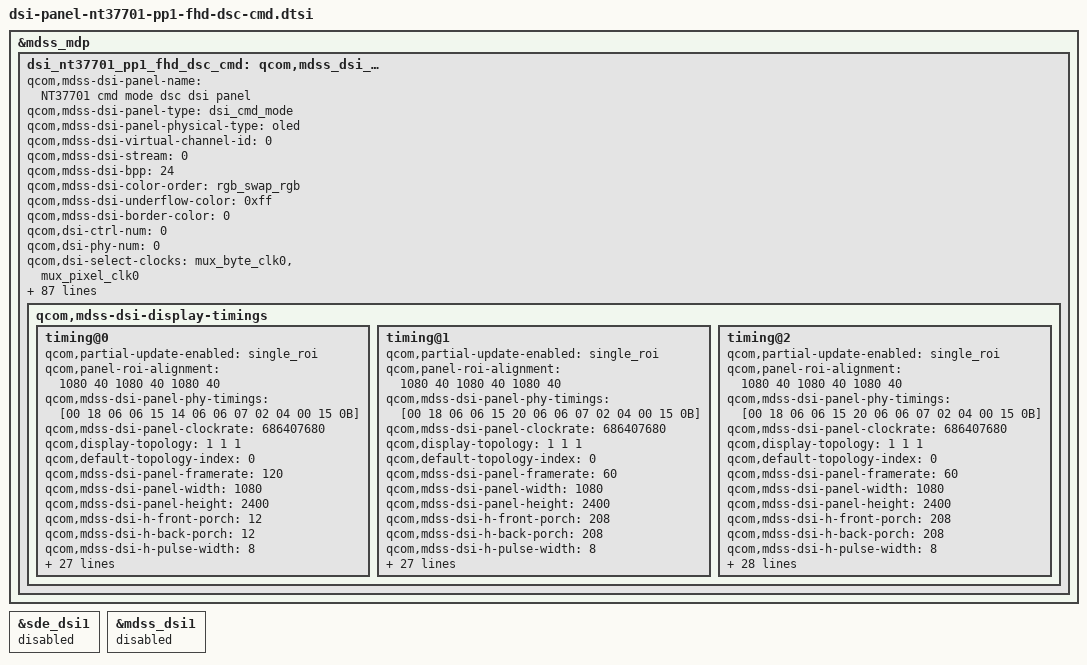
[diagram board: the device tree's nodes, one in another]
/* Copyright (c) 2014, Code Aurora Forum. All rights reserved.
 *
 * This program is free software; you can redistribute it and/or modify
 * it under the terms of the GNU General Public License version 2 and
 * only version 2 as published by the Free Software Foundation.
 *
 * This program is distributed in the hope that it will be useful,
 * but WITHOUT ANY WARRANTY; without even the implied warranty of
 * MERCHANTABILITY or FITNESS FOR A PARTICULAR PURPOSE.  See the
 * GNU General Public License for more details.
 */

&mdss_mdp {
    dsi_nt37701_pp1_fhd_dsc_cmd: qcom,mdss_dsi_nt37701_pp1_fhd_dsc_cmd {
        qcom,mdss-dsi-panel-name = "NT37701 cmd mode dsc dsi panel";
		qcom,mdss-dsi-panel-type = "dsi_cmd_mode";
		qcom,mdss-dsi-panel-physical-type = "oled";
		qcom,mdss-dsi-virtual-channel-id = <0>;
		qcom,mdss-dsi-stream = <0>;
		qcom,mdss-dsi-bpp = <24>;
		qcom,mdss-dsi-color-order = "rgb_swap_rgb";
		qcom,mdss-dsi-underflow-color = <0xff>;
		qcom,mdss-dsi-border-color = <0>;
		qcom,dsi-ctrl-num = <0>;
		qcom,dsi-phy-num = <0>;
		qcom,dsi-select-clocks = "mux_byte_clk0", "mux_pixel_clk0";
		qcom,mdss-dsi-traffic-mode = "burst_mode";
		qcom,mdss-dsi-lane-map = "lane_map_0123";
		qcom,mdss-dsi-bllp-eof-power-mode;
		qcom,mdss-dsi-bllp-power-mode;
		qcom,mdss-dsi-lane-0-state;
		qcom,mdss-dsi-lane-1-state;
		qcom,mdss-dsi-lane-2-state;
		qcom,mdss-dsi-lane-3-state;
		qcom,mdss-dsi-reset-sequence = <1 10>, <0 2>, <1 10>;
		lge,mdss-dsi-reset-keep-high-after-off-cmd = <180>;
		qcom,mdss-dsi-dma-trigger = "trigger_sw";
		qcom,mdss-dsi-mdp-trigger = "none";
		qcom,mdss-dsi-te-pin-select = <1>;
		qcom,mdss-dsi-wr-mem-start = <0x2c>;
		qcom,mdss-dsi-wr-mem-continue = <0x3c>;
		qcom,mdss-dsi-te-dcs-command = <1>;
		//qcom,mdss-dsi-te-check-enable;
		//qcom,mdss-dsi-te-using-te-pin;
		qcom,mdss-dsi-lp11-init;
		qcom,mdss-dsi-tx-eot-append;
		qcom,ulps-enabled;
		//qcom,suspend-ulps-enabled;
		qcom,mdss-pan-physical-width-dimension = <71>;
		qcom,mdss-pan-physical-height-dimension = <157>;


		/********** HDR **********/
		qcom,mdss-dsi-panel-hdr-enabled;
		qcom,mdss-dsi-panel-hdr-color-primaries = <14880 15935 32435 16555 14945 30910 7790 3415>;
		qcom,mdss-dsi-panel-peak-brightness = <5000000>;		/* max. 500nits */
		qcom,mdss-dsi-panel-blackness-level = <6134>;

		/********** Brightness list **********/
		lge,blmap = <
			0
			44 44 44 44 44 44 44 44 44 44 52 60 69 77 85 93 102 110 118 126
			135 143 151 159 167 176 184 192 200 209 217 225 233 242 250 258 271 284 298 311
			324 337 351 364 377 390 404 417 430 443 457 470 483 496 510 523 536 549 563 576
			589 605 622 638 654 670 687 703 719 735 752 768 784 800 817 833 849 865 882 898
			914 931 948 965 979 996 1013 1030 1047 1064 1080 1097 1114 1131 1148 1165 1182 1199 1216 1233
			1250 1267 1283 1300 1317 1334 1351 1368 1382 1396 1411 1425 1439 1453 1468 1482 1496 1510 1525 1539
			1553 1567 1581 1596 1610 1624 1638 1653 1667 1681 1695 1710 1724 1738 1754 1769 1785 1800 1816 1832
			1847 1861 1877 1893 1908 1924 1939 1955 1971 1986 2002 2017 2033 2049 2064 2080 2095 2111 2128 2143
			2158 2173 2188 2203 2218 2233 2248 2263 2278 2293 2309 2324 2339 2354 2369 2384 2399 2414 2429 2444
			2459 2474 2489 2503 2518 2532 2547 2561 2576 2590 2605 2619 2634 2648 2663 2677 2691 2706 2720 2735
			2749 2764 2778 2793 2807 2822 2836 2850 2863 2877 2891 2904 2918 2932 2945 2959 2973 2986 3000 3014
			3028 3041 3055 3069 3082 3096 3110 3123 3137 3151 3164 3178 3193 3207 3222 3237 3252 3266 3281 3296
			3311 3325 3340 3355 3370 3384 3399 3414 3429 3443 3458 3473 3488 3502 3517 3521 3525 3529 3534 3538
			3542 3546 3550 3554 3559 3563 3567 3571 3575 3579 3583 3588 3592 3596 3600 3605 3611 3616 3622 3627
			3633 3638 3644 3649 3655 3660 3666 3671 3677 3682 3687 3693 3698 3704 3709 3715 3720 3726 3731 3737
			3742 3748 3753 3759 3764 3769 3775 3780 3786 3791 3797 3802 3808 3813 3819 3824 3830 3835 3841 3846
			3851 3857 3862 3868 3873 3879 3884 3890 3895 3901 3906 3912 3917 3923 3928 3933 3939 3944 3950 3955
			3961 3966 3972 3977 3983 3988 3994 3999 4005 4010 4016 4021 4027 4033 4038 4044 4050 4055 4061 4067
			4072 4078 4084 4089 4095
		>;

		lge,blmap-daylight = <
			0
			44 44 44 44 44 44 44 44 44 44 54 63 73 83 92 102 112 122 131 141
			151 160 170 180 189 199 209 218 228 238 248 257 267 277 286 296 312 327 343 358
			374 389 405 420 436 451 467 482 498 513 529 544 560 575 591 606 622 637 653 668
			684 702 721 739 758 776 795 813 832 850 869 887 906 924 942 961 979 998 1016 1035
			1053 1071 1090 1108 1127 1145 1164 1182 1200 1219 1237 1255 1273 1292 1310 1328 1347 1365 1383 1402
			1420 1438 1456 1475 1493 1511 1530 1548 1565 1583 1600 1617 1635 1652 1669 1687 1704 1721 1739 1756
			1774 1791 1808 1826 1843 1860 1878 1895 1912 1930 1947 1964 1982 1999 2015 2032 2048 2064 2080 2097
			2113 2130 2147 2163 2179 2195 2212 2228 2244 2261 2277 2293 2309 2326 2342 2358 2375 2391 2406 2422
			2438 2455 2471 2487 2503 2519 2535 2552 2568 2584 2600 2616 2632 2649 2665 2681 2697 2713 2729 2746
			2762 2778 2794 2811 2827 2844 2860 2877 2893 2910 2926 2943 2959 2976 2992 3009 3025 3042 3058 3075
			3091 3108 3124 3141 3157 3174 3190 3206 3223 3239 3255 3272 3288 3304 3321 3337 3353 3370 3386 3402
			3418 3435 3451 3467 3484 3500 3516 3533 3549 3565 3582 3598 3620 3641 3663 3684 3706 3728 3749 3771
			3792 3814 3836 3857 3879 3901 3922 3944 3965 3987 4009 4030 4052 4073 4095 4095 4095 4095 4095 4095
			4095 4095 4095 4095 4095 4095 4095 4095 4095 4095 4095 4095 4095 4095 4095 4095 4095 4095 4095 4095
			4095 4095 4095 4095 4095 4095 4095 4095 4095 4095 4095 4095 4095 4095 4095 4095 4095 4095 4095 4095
			4095 4095 4095 4095 4095 4095 4095 4095 4095 4095 4095 4095 4095 4095 4095 4095 4095 4095 4095 4095
			4095 4095 4095 4095 4095 4095 4095 4095 4095 4095 4095 4095 4095 4095 4095 4095 4095 4095 4095 4095
			4095 4095 4095 4095 4095 4095 4095 4095 4095 4095 4095 4095 4095 4095 4095 4095 4095 4095 4095 4095
			4095 4095 4095 4095 4095
		>;

		lge,blmap-hdr = <
			0
			44 44 44 44 44 44 44 44 44 44 52 60 69 77 85 93 102 110 118 126
			135 143 151 159 167 176 184 192 200 209 217 225 233 242 250 258 271 284 298 311
			324 337 351 364 377 390 404 417 430 443 457 470 483 496 510 523 536 549 563 576
			589 605 622 638 654 670 687 703 719 735 752 768 784 800 817 833 849 865 882 898
			914 931 948 965 979 996 1013 1030 1047 1064 1080 1097 1114 1131 1148 1165 1182 1199 1216 1233
			1250 1267 1283 1300 1317 1334 1351 1368 1382 1396 1411 1425 1439 1453 1468 1482 1496 1510 1525 1539
			1553 1567 1581 1596 1610 1624 1638 1653 1667 1681 1695 1710 1724 1738 1754 1769 1785 1800 1816 1832
			1847 1861 1877 1893 1908 1924 1939 1955 1971 1986 2002 2017 2033 2049 2064 2080 2095 2111 2128 2143
			2158 2173 2188 2203 2218 2233 2248 2263 2278 2293 2309 2324 2339 2354 2369 2384 2399 2414 2429 2444
			2459 2474 2489 2503 2518 2532 2547 2561 2576 2590 2605 2619 2634 2648 2663 2677 2691 2706 2720 2735
			2749 2764 2778 2793 2807 2822 2836 2850 2863 2877 2891 2904 2918 2932 2945 2959 2973 2986 3000 3014
			3028 3041 3055 3069 3082 3096 3110 3123 3137 3151 3164 3178 3193 3207 3222 3237 3252 3266 3281 3296
			3311 3325 3340 3355 3370 3384 3399 3414 3429 3443 3458 3473 3488 3502 3517 3521 3525 3529 3534 3538
			3542 3546 3550 3554 3559 3563 3567 3571 3575 3579 3583 3588 3592 3596 3600 3605 3611 3616 3622 3627
			3633 3638 3644 3649 3655 3660 3666 3671 3677 3682 3687 3693 3698 3704 3709 3715 3720 3726 3731 3737
			3742 3748 3753 3759 3764 3769 3775 3780 3786 3791 3797 3802 3808 3813 3819 3824 3830 3835 3841 3846
			3851 3857 3862 3868 3873 3879 3884 3890 3895 3901 3906 3912 3917 3923 3928 3933 3939 3944 3950 3955
			3961 3966 3972 3977 3983 3988 3994 3999 4005 4010 4016 4021 4027 4033 4038 4044 4050 4055 4061 4067
			4072 4078 4084 4089 4095
		>;

		lge,blmap-hdr-daylight = <
			0
			44 44 44 44 44 44 44 44 44 44 54 63 73 83 92 102 112 122 131 141
			151 160 170 180 189 199 209 218 228 238 248 257 267 277 286 296 312 327 343 358
			374 389 405 420 436 451 467 482 498 513 529 544 560 575 591 606 622 637 653 668
			684 702 721 739 758 776 795 813 832 850 869 887 906 924 942 961 979 998 1016 1035
			1053 1071 1090 1108 1127 1145 1164 1182 1200 1219 1237 1255 1273 1292 1310 1328 1347 1365 1383 1402
			1420 1438 1456 1475 1493 1511 1530 1548 1565 1583 1600 1617 1635 1652 1669 1687 1704 1721 1739 1756
			1774 1791 1808 1826 1843 1860 1878 1895 1912 1930 1947 1964 1982 1999 2015 2032 2048 2064 2080 2097
			2113 2130 2147 2163 2179 2195 2212 2228 2244 2261 2277 2293 2309 2326 2342 2358 2375 2391 2406 2422
			2438 2455 2471 2487 2503 2519 2535 2552 2568 2584 2600 2616 2632 2649 2665 2681 2697 2713 2729 2746
			2762 2778 2794 2811 2827 2844 2860 2877 2893 2910 2926 2943 2959 2976 2992 3009 3025 3042 3058 3075
			3091 3108 3124 3141 3157 3174 3190 3206 3223 3239 3255 3272 3288 3304 3321 3337 3353 3370 3386 3402
			3418 3435 3451 3467 3484 3500 3516 3533 3549 3565 3582 3598 3620 3641 3663 3684 3706 3728 3749 3771
			3792 3814 3836 3857 3879 3901 3922 3944 3965 3987 4009 4030 4052 4073 4095 4095 4095 4095 4095 4095
			4095 4095 4095 4095 4095 4095 4095 4095 4095 4095 4095 4095 4095 4095 4095 4095 4095 4095 4095 4095
			4095 4095 4095 4095 4095 4095 4095 4095 4095 4095 4095 4095 4095 4095 4095 4095 4095 4095 4095 4095
			4095 4095 4095 4095 4095 4095 4095 4095 4095 4095 4095 4095 4095 4095 4095 4095 4095 4095 4095 4095
			4095 4095 4095 4095 4095 4095 4095 4095 4095 4095 4095 4095 4095 4095 4095 4095 4095 4095 4095 4095
			4095 4095 4095 4095 4095 4095 4095 4095 4095 4095 4095 4095 4095 4095 4095 4095 4095 4095 4095 4095
			4095 4095 4095 4095 4095
		>;

		lge,blmap-ex = <
			0
			340 340 340 340 340 340 340 340 340 362 384 406 428 450 472 494 516 538 560 582
			604 626 648 670 692 714 736 758 780 802 824 846 868 890 912 934 954 974 994 1014
			1034 1054 1073 1093 1113 1133 1153 1173 1193 1213 1233 1253 1273 1293 1313 1332 1352 1372 1392 1412
			1432 1452 1472 1492 1512 1532 1552 1572 1591 1611 1631 1651 1671 1691 1711 1746 1780 1815 1850 1885
			1919 1954 1989 2024 2058 2093 2128 2162 2197 2232 2267 2301 2336 2371 2406 2440 2475 2506 2536 2567
			2597 2628 2659 2689 2720 2751 2781 2812 2842 2873 2904 2934 2965 2995 3026 3049 3073 3096 3120 3143
			3167 3190 3214 3237 3261 3284 3308 3331 3355 3378 3402 3425 3449 3472 3524 3576 3628 3679 3731 3783
			3799 3816 3832 3849 3865 3882 3898 3914 3931 3947 3964 3980 3996 4013 4029 4046 4062 4079 4095 4095
			4095 4095 4095 4095 4095 4095 4095 4095 4095 4095 4095 4095 4095 4095 4095 4095 4095 4095 4095 4095
			4095 4095 4095 4095 4095 4095 4095 4095 4095 4095 4095 4095 4095 4095 4095 4095 4095 4095 4095 4095
			4095 4095 4095 4095 4095 4095 4095 4095 4095 4095 4095 4095 4095 4095 4095 4095 4095 4095 4095 4095
			4095 4095 4095 4095 4095 4095 4095 4095 4095 4095 4095 4095 4095 4095 4095 4095 4095 4095 4095 4095
			4095 4095 4095 4095 4095 4095 4095 4095 4095 4095 4095 4095 4095 4095 4095 4095 4095 4095 4095 4095
			4095 4095 4095 4095 4095 4095 4095 4095 4095 4095 4095 4095 4095 4095 4095
		>;
		lge,use-vr-lp-mode;
		lge,mdss-dsi-vr-lp-mode-on-command = [
			39 00 00 00 00 00 06 F0 55 AA 52 08 00
			39 00 00 00 00 00 10 B2 11 00 20 20 00 08 08 00 00 40 30 00 00 00 00
			15 00 00 00 00 00 02 6F 0F
			39 00 00 00 00 00 0C B2 30 20 24 24 24 24 2F FF 00 00 00
			39 01 00 00 00 00 06 F0 55 AA 52 00 00
		];
		lge,mdss-dsi-vr-lp-mode-off-command = [
			39 00 00 00 00 00 06 F0 55 AA 52 08 00
			39 00 00 00 00 00 10 B2 01 00 20 20 00 08 08 00 00 40 30 00 00 00 00
			15 00 00 00 00 00 02 6F 0F
			39 00 00 00 00 00 0C B2 30 20 25 89 25 89 2F FF 00 00 00
			39 01 00 00 00 00 06 F0 55 AA 52 00 00
		];
		lge,mdss-dsi-vr-lp-command-state = "dsi_lp_mode";
		lge,blmap-vr = < 0 1060 >;

		/********** Color Manager **********/
		lge,use-color-manager;
		lge,color-manager-default-status = <1>;
		lge,mdss-dsi-color-manager-mode-table = <0 1>, <1 1>, <2 1>, <3 1>;

		lge,mdss-dsi-disp-ctrl-command-1 = [
			//------------------ CM on/off ---------------------
			15 01 00 00 00 00 02 55 00
		];
		lge,mdss-dsi-disp-ctrl-command-1-state = "dsi_lp_mode";

		lge,mdss-dsi-saturation-command = [
			39 00 00 00 00 00 06 F0 55 AA 52 08 00
			39 00 00 00 00 00 2E D1 35 35 35 35 32 30 30 30 32 2D 2D 29 29 32 32 35 35 35 35 33 32 33 35 35 03 01 01 01 01 01 01 01 02 01 01 01 01 06 0C 03 09 0F 68 88 00
			39 01 00 00 00 00 06 F0 55 AA 52 00 00
		];
		lge,mdss-dsi-saturation-command-state = "dsi_hs_mode";

		lge,mdss-dsi-hue-command = [
			39 00 00 00 00 00 06 F0 55 AA 52 08 00
			39 00 00 00 00 00 34 D2 77 0C 40 80 80 8E 80 80 80 80 40 40 40 80 80 80 AD AD A0 80 80 80 80 80 80 80 80 80 80 80 80 80 80 80 80 80 80 80 80 80 80 80 80 80 80 80 80 80 80 80 80
			39 01 00 00 00 00 06 F0 55 AA 52 00 00
		];
		lge,mdss-dsi-hue-command-state = "dsi_hs_mode";

		lge,mdss-dsi-sharpness-command = [
			39 00 00 00 00 00 06 F0 55 AA 52 08 00
			39 00 00 00 00 00 07 D3 02 00 00 01 10 00
			39 01 00 00 00 00 06 F0 55 AA 52 00 00
		];
		lge,mdss-dsi-sharpness-command-state = "dsi_hs_mode";

		lge,mdss-dsi-cm-natural = [
			39 00 00 00 00 00 06 F0 55 AA 52 08 00
			15 00 00 00 00 00 02 6F 00
			39 00 00 00 00 00 13 CE 00 40 40 40 40 3D 3D 3D 3D 40 40 40 40 40 40 40 40 40
			15 00 00 00 00 00 02 6F 13
			39 00 00 00 00 00 12 CE 45 45 45 45 45 45 45 45 45 45 45 45 45 45 45 45 40
			15 00 00 00 00 00 02 6F 24
			39 00 00 00 00 00 12 CE 42 42 42 42 42 42 42 42 42 42 42 42 42 42 42 40 40
			15 00 00 00 00 00 02 6F 35
			39 00 00 00 00 00 12 CE 40 40 40 40 40 40 40 40 40 40 40 40 40 40 40 40 40
			39 00 00 00 00 00 2E D1 32 33 32 35 32 30 30 2F 2D 2D 2D 29 29 29 32 35 35 35 35 33 32 33 35 35 03 01 01 01 01 01 01 01 02 01 01 01 01 06 0C 03 09 0F 68 88 00
			39 00 00 00 00 00 34 D2 77 0C 40 80 80 7F 80 80 80 80 80 80 80 80 80 80 A8 A8 A0 80 80 80 80 80 80 80 80 80 80 80 80 80 80 80 80 40 40 80 80 80 80 80 80 80 80 80 80 80 80 80 80
			39 00 00 00 00 00 07 D3 00 00 00 00 00 00
			39 00 00 00 00 00 06 F0 55 AA 52 08 07
			39 00 00 00 00 00 03 C0 01 0A
			39 01 00 00 00 00 06 F0 55 AA 52 00 00
		];
		lge,mdss-dsi-cm-natural-state = "dsi_hs_mode";

		lge,mdss-dsi-cm-vivid = [
			39 00 00 00 00 00 06 F0 55 AA 52 08 00
			15 00 00 00 00 00 02 6F 00
			39 00 00 00 00 00 13 CE 00 40 40 40 40 40 40 40 40 40 40 40 40 40 40 40 40 40
			15 00 00 00 00 00 02 6F 13
			39 00 00 00 00 00 12 CE 40 40 40 40 40 40 40 40 40 40 40 40 40 40 40 40 40
			15 00 00 00 00 00 02 6F 24
			39 00 00 00 00 00 12 CE 40 40 40 40 40 40 40 40 40 40 40 40 40 40 40 40 40
			15 00 00 00 00 00 02 6F 35
			39 00 00 00 00 00 12 CE 40 40 40 40 40 40 40 40 40 40 40 40 40 40 40 40 40
			39 00 00 00 00 00 2E D1 50 35 35 35 50 50 50 50 50 50 50 50 50 50 50 50 50 50 50 50 50 50 50 50 01 01 01 01 01 01 01 01 01 01 01 01 00 06 0C 03 09 0F 68 88 00
			39 00 00 00 00 00 34 D2 77 0C 40 80 80 95 80 80 80 80 80 80 80 80 80 80 80 80 80 80 80 80 80 80 80 80 80 80 80 80 80 80 80 80 80 80 80 80 80 80 80 80 80 80 80 80 80 80 80 80 80
			39 00 00 00 00 00 07 D3 00 00 00 00 00 00
			39 00 00 00 00 00 06 F0 55 AA 52 08 07
			39 00 00 00 00 00 03 C0 01 0A
			39 01 00 00 00 00 06 F0 55 AA 52 00 00
		];
		lge,mdss-dsi-cm-vivid-state = "dsi_hs_mode";

		lge,mdss-dsi-cm-cinema = [
			39 00 00 00 00 00 06 F0 55 AA 52 08 00
			15 00 00 00 00 00 02 6F 00
			39 00 00 00 00 00 13 CE 00 40 40 44 44 44 44 44 44 44 44 44 44 44 44 44 44 40
			15 00 00 00 00 00 02 6F 13
			39 00 00 00 00 00 12 CE 40 40 40 40 40 40 40 40 40 40 40 40 40 40 40 40 40
			15 00 00 00 00 00 02 6F 24
			39 00 00 00 00 00 12 CE 43 43 43 43 43 43 43 43 43 43 43 48 48 48 48 48 50
			15 00 00 00 00 00 02 6F 35
			39 00 00 00 00 00 12 CE 44 44 44 44 44 44 44 44 44 44 44 44 44 44 44 44 45
			39 00 00 00 00 00 2E D1 35 35 35 35 35 35 37 37 38 35 30 2C 2C 2C 30 32 35 35 35 35 35 34 33 35 44 14 11 11 11 11 11 15 11 11 21 44 00 06 0C 03 09 0F 68 88 00
			39 00 00 00 00 00 34 D2 77 0C 40 80 80 8D 85 80 80 70 60 50 60 7A 80 80 80 8A 8A 8A 80 7B 7B 78 76 74 80 80 80 80 80 80 80 80 80 80 80 80 80 80 80 80 80 80 80 80 80 80 80 80 80
			39 00 00 00 00 00 07 D3 00 00 00 00 00 00
			39 00 00 00 00 00 06 F0 55 AA 52 08 07
			39 00 00 00 00 00 03 C0 01 0A
			39 01 00 00 00 00 06 F0 55 AA 52 00 00
		];
		lge,mdss-dsi-cm-cinema-state = "dsi_hs_mode";

		/********** FPS control **********/
		lge,fps-switch-enabled;
		lge,mdss-dsi-switch-fps-ctrl-command = [
			39 01 00 00 00 00 02 2F 00
		];
		lge,mdss-dsi-switch-fps-ctrl-command-state = "dsi_lp_mode";

		/********** AOD **********/
		lge,disp-br-ctrl-ext-supported;
		lge,ddic-dsi-br-ctrl-ext-command = [
			39 01 00 00 00 00 05 51 00 00 00 00
		];

		lge,mdss-dsi-nolp-command = [
			39 00 00 00 00 00 06 F0 55 AA 52 08 00
			39 00 00 00 00 00 02 6F 0B
			39 00 00 00 00 00 04 B5 4E 29 50
			39 01 00 00 00 00 06 F0 55 AA 52 00 00
			39 01 00 00 00 00 02 65 00
			05 01 00 00 00 00 01 38
		];
		lge,mdss-dsi-nolp-command-state = "dsi_lp_mode";
		lge,mdss-dsi-lp2-command = [
			39 00 00 00 00 00 06 F0 55 AA 52 08 00
			39 00 00 00 00 00 02 6F 0B
			39 00 00 00 00 00 04 B5 4E 29 51
			15 00 00 00 00 00 02 55 00
			39 00 00 00 00 00 06 F0 55 AA 52 08 07
			39 00 00 00 00 00 03 C0 01 02
			39 01 00 00 00 00 06 F0 55 AA 52 00 00
			39 01 00 00 00 00 02 2F 01
			05 01 00 00 40 00 01 39
			39 01 00 00 00 00 02 65 01
		];
		lge,mdss-dsi-lp2-command-state = "dsi_lp_mode";

		//lge,use-dim-ctrl;
		lge,send-partial-update-cmds-to-hs;


		qcom,mdss-dsi-display-timings {
			timing@0{
				qcom,partial-update-enabled = "single_roi";
				qcom,panel-roi-alignment = <1080 40 1080 40 1080 40>;
				qcom,mdss-dsi-panel-phy-timings = [00 18 06 06 15 14 06 06 07 02 04 00 15 0B];
				qcom,mdss-dsi-panel-clockrate = <686407680>;
				qcom,display-topology = <1 1 1>;
				qcom,default-topology-index = <0>;
				qcom,mdss-dsi-panel-framerate = <120>;
				qcom,mdss-dsi-panel-width = <1080>;
				qcom,mdss-dsi-panel-height = <2400>;
				qcom,mdss-dsi-h-front-porch = <12>;
				qcom,mdss-dsi-h-back-porch = <12>;
				qcom,mdss-dsi-h-pulse-width = <8>;
				qcom,mdss-dsi-h-sync-skew = <0>;
				qcom,mdss-dsi-v-back-porch = <14>;
				qcom,mdss-dsi-v-front-porch = <16>;
				qcom,mdss-dsi-v-pulse-width = <2>;
				qcom,mdss-dsi-h-left-border = <0>;
				qcom,mdss-dsi-h-right-border = <0>;
				qcom,mdss-dsi-v-top-border = <0>;
				qcom,mdss-dsi-v-bottom-border = <0>;
				qcom,mdss-dsi-h-sync-pulse = <0>;
				//qcom,mdss-mdp-transfer-time-us = <7601>;

				qcom,mdss-dsi-on-command = [
					//------------------ Page Disable ---------------------
					39 01 00 00 00 00 06 F0 55 AA 52 00 00
					39 01 00 00 00 00 05 FF AA 55 A5 00

					//----------------------- CMD1 ------------------------
					39 01 00 00 00 00 01 35
					39 01 00 00 00 00 02 53 20
					39 01 00 00 00 00 05 51 0D BB 0F FE
					39 01 00 00 00 00 05 2A 00 00 04 37
					39 01 00 00 00 00 05 2B 00 00 09 5F

					// ##compression method selection, slice high 40 (1-dec)
					39 01 00 00 00 00 02 03 01
					39 01 00 00 00 00 02 90 01
					39 01 00 00 00 00 13 91 89 28 00 28 C2 00 03 1C 05 2D 00 0F 02 77 01 46 10 F0
					39 01 00 00 00 00 01 2C

					// ##ELVSS swire offset
					39 01 00 00 00 00 02 82 A6

					//----------------------- CM common setting ------------------------
					39 01 00 00 00 00 06 F0 55 AA 52 08 00
					39 01 00 00 00 00 19 CC 40 40 40 40 40 40 40 40 40 40 40 40 40 40 40 40 40 50 60 70 58 68 78 77
					15 01 00 00 00 00 02 6F 46
					39 01 00 00 00 00 12 CE 40 40 40 40 40 40 40 40 40 40 40 40 40 40 40 40 40
					15 01 00 00 00 00 02 6F 57
					39 01 00 00 00 00 12 CE 40 40 40 40 40 40 40 40 40 40 40 40 40 40 40 40 40
					15 01 00 00 00 00 02 6F 00
					39 01 00 00 00 00 03 D0 77 00
					15 01 00 00 00 00 02 6F 01
					39 01 00 00 00 00 03 D4 00 00
					39 01 00 00 00 00 19 DE 00 00 00 00 00 00 00 00 00 00 00 00 10 00 00 00 00 00 00 00 10 00 00 00
					39 01 00 00 00 00 06 F0 55 AA 52 00 00

					//----------------- ##Frame rate=120Hz-----------------
					39 01 00 00 00 00 02 2F 02
					05 01 00 00 78 00 01 11
					05 01 00 00 00 00 01 29
				];

				qcom,mdss-dsi-off-command = [
					39 01 00 00 00 00 06 F0 55 AA 52 08 01
					39 01 00 00 00 00 02 CE 0C
					05 01 00 00 78 00 01 28
					05 01 00 00 96 00 01 10
				];

				qcom,compression-mode = "dsc";
				qcom,mdss-dsc-version = <0x11>;
				qcom,mdss-dsc-scr-version = <0x0>;
				qcom,mdss-dsc-slice-height = <40>;
				qcom,mdss-dsc-slice-width = <1080>;
				qcom,mdss-dsc-slice-per-pkt = <1>;
				qcom,mdss-dsc-bit-per-component = <8>;
				qcom,mdss-dsc-bit-per-pixel = <8>;
				qcom,mdss-dsc-encoders = <1>;
				qcom,mdss-dsc-block-prediction-enable;

				qcom,mdss-dsi-on-command-state = "dsi_lp_mode";
				qcom,mdss-dsi-off-command-state = "dsi_lp_mode";

				qcom,mode-control-dsi-state = "dsi_lp_mode";
				qcom,mdss-dsi-pps-command-state = "dsi_hs_mode";
			};
			timing@1{
				qcom,partial-update-enabled = "single_roi";
				qcom,panel-roi-alignment = <1080 40 1080 40 1080 40>;
				qcom,mdss-dsi-panel-phy-timings = [00 18 06 06 15 20 06 06 07 02 04 00 15 0B];
				qcom,mdss-dsi-panel-clockrate = <686407680>;
				qcom,display-topology = <1 1 1>;
				qcom,default-topology-index = <0>;
				qcom,mdss-dsi-panel-framerate = <60>;
				qcom,mdss-dsi-panel-width = <1080>;
				qcom,mdss-dsi-panel-height = <2400>;
				qcom,mdss-dsi-h-front-porch = <208>;
				qcom,mdss-dsi-h-back-porch = <208>;
				qcom,mdss-dsi-h-pulse-width = <8>;
				qcom,mdss-dsi-h-sync-skew = <0>;
				qcom,mdss-dsi-v-back-porch = <14>;
				qcom,mdss-dsi-v-front-porch = <16>;
				qcom,mdss-dsi-v-pulse-width = <2>;
				qcom,mdss-dsi-h-left-border = <0>;
				qcom,mdss-dsi-h-right-border = <0>;
				qcom,mdss-dsi-v-top-border = <0>;
				qcom,mdss-dsi-v-bottom-border = <0>;
				qcom,mdss-dsi-h-sync-pulse = <0>;
				//qcom,mdss-mdp-transfer-time-us = <7601>;

				qcom,mdss-dsi-on-command = [
					//------------------ Page Disable ---------------------
					39 01 00 00 00 00 06 F0 55 AA 52 00 00
					39 01 00 00 00 00 05 FF AA 55 A5 00

					//----------------------- CMD1 ------------------------
					39 01 00 00 00 00 01 35
					39 01 00 00 00 00 02 53 20
					39 01 00 00 00 00 05 51 0D BB 0F FE
					39 01 00 00 00 00 05 2A 00 00 04 37
					39 01 00 00 00 00 05 2B 00 00 09 5F

					// ##compression method selection, slice high 40 (1-dec)
					39 01 00 00 00 00 02 03 01
					39 01 00 00 00 00 02 90 01
					39 01 00 00 00 00 13 91 89 28 00 28 C2 00 03 1C 05 2D 00 0F 02 77 01 46 10 F0
					39 01 00 00 00 00 01 2C

					// ##ELVSS swire offset
					39 01 00 00 00 00 02 82 A6

					//----------------------- CM common setting ------------------------
					39 01 00 00 00 00 06 F0 55 AA 52 08 00
					39 01 00 00 00 00 19 CC 40 40 40 40 40 40 40 40 40 40 40 40 40 40 40 40 40 50 60 70 58 68 78 77
					15 01 00 00 00 00 02 6F 46
					39 01 00 00 00 00 12 CE 40 40 40 40 40 40 40 40 40 40 40 40 40 40 40 40 40
					15 01 00 00 00 00 02 6F 57
					39 01 00 00 00 00 12 CE 40 40 40 40 40 40 40 40 40 40 40 40 40 40 40 40 40
					15 01 00 00 00 00 02 6F 00
					39 01 00 00 00 00 03 D0 77 00
					15 01 00 00 00 00 02 6F 01
					39 01 00 00 00 00 03 D4 00 00
					39 01 00 00 00 00 19 DE 00 00 00 00 00 00 00 00 00 00 00 00 10 00 00 00 00 00 00 00 10 00 00 00
					39 01 00 00 00 00 06 F0 55 AA 52 00 00

					//----------------- ##Frame rate=60Hz-----------------
					39 01 00 00 00 00 02 2F 01
					05 01 00 00 78 00 01 11
					05 01 00 00 00 00 01 29
					];

				qcom,mdss-dsi-off-command = [
					39 01 00 00 00 00 06 F0 55 AA 52 08 01
					39 01 00 00 00 00 02 CE 0C
					05 01 00 00 78 00 01 28
					05 01 00 00 96 00 01 10
				];

				qcom,compression-mode = "dsc";
				qcom,mdss-dsc-version = <0x11>;
				qcom,mdss-dsc-scr-version = <0x0>;
				qcom,mdss-dsc-slice-height = <40>;
				qcom,mdss-dsc-slice-width = <1080>;
				qcom,mdss-dsc-slice-per-pkt = <1>;
				qcom,mdss-dsc-bit-per-component = <8>;
				qcom,mdss-dsc-bit-per-pixel = <8>;
				qcom,mdss-dsc-encoders = <1>;
				qcom,mdss-dsc-block-prediction-enable;

				qcom,mdss-dsi-on-command-state = "dsi_lp_mode";
				qcom,mdss-dsi-off-command-state = "dsi_lp_mode";

				qcom,mode-control-dsi-state = "dsi_lp_mode";
				qcom,mdss-dsi-pps-command-state = "dsi_hs_mode";
			};
			timing@2{
				qcom,partial-update-enabled = "single_roi";
				qcom,panel-roi-alignment = <1080 40 1080 40 1080 40>;
				qcom,mdss-dsi-panel-phy-timings = [00 18 06 06 15 20 06 06 07 02 04 00 15 0B];
				qcom,mdss-dsi-panel-clockrate = <686407680>;
				qcom,display-topology = <1 1 1>;
				qcom,default-topology-index = <0>;
				qcom,mdss-dsi-panel-framerate = <60>;
				qcom,mdss-dsi-panel-width = <1080>;
				qcom,mdss-dsi-panel-height = <2400>;
				qcom,mdss-dsi-h-front-porch = <208>;
				qcom,mdss-dsi-h-back-porch = <208>;
				qcom,mdss-dsi-h-pulse-width = <8>;
				qcom,mdss-dsi-h-sync-skew = <0>;
				qcom,mdss-dsi-v-back-porch = <14>;
				qcom,mdss-dsi-v-front-porch = <16>;
				qcom,mdss-dsi-v-pulse-width = <2>;
				qcom,mdss-dsi-h-left-border = <0>;
				qcom,mdss-dsi-h-right-border = <0>;
				qcom,mdss-dsi-v-top-border = <0>;
				qcom,mdss-dsi-v-bottom-border = <0>;
				qcom,mdss-dsi-h-sync-pulse = <0>;
				//qcom,mdss-mdp-transfer-time-us = <7601>;
				lge,mdss-dsi-panel-framerate-div = <2>;

				qcom,mdss-dsi-on-command = [
					//------------------ Page Disable ---------------------
					39 01 00 00 00 00 06 F0 55 AA 52 00 00
					39 01 00 00 00 00 05 FF AA 55 A5 00

					//----------------------- CMD1 ------------------------
					39 01 00 00 00 00 01 35
					39 01 00 00 00 00 02 53 20
					39 01 00 00 00 00 05 51 0D BB 0F FE
					39 01 00 00 00 00 05 2A 00 00 04 37
					39 01 00 00 00 00 05 2B 00 00 09 5F

					// ##compression method selection, slice high 40 (1-dec)
					39 01 00 00 00 00 02 03 01
					39 01 00 00 00 00 02 90 01
					39 01 00 00 00 00 13 91 89 28 00 28 C2 00 03 1C 05 2D 00 0F 02 77 01 46 10 F0
					39 01 00 00 00 00 01 2C

					// ##ELVSS swire offset
					39 01 00 00 00 00 02 82 A6

					//----------------------- CM common setting ------------------------
					39 01 00 00 00 00 06 F0 55 AA 52 08 00
					39 01 00 00 00 00 19 CC 40 40 40 40 40 40 40 40 40 40 40 40 40 40 40 40 40 50 60 70 58 68 78 77
					15 01 00 00 00 00 02 6F 46
					39 01 00 00 00 00 12 CE 40 40 40 40 40 40 40 40 40 40 40 40 40 40 40 40 40
					15 01 00 00 00 00 02 6F 57
					39 01 00 00 00 00 12 CE 40 40 40 40 40 40 40 40 40 40 40 40 40 40 40 40 40
					15 01 00 00 00 00 02 6F 00
					39 01 00 00 00 00 03 D0 77 00
					15 01 00 00 00 00 02 6F 01
					39 01 00 00 00 00 03 D4 00 00
					39 01 00 00 00 00 19 DE 00 00 00 00 00 00 00 00 00 00 00 00 10 00 00 00 00 00 00 00 10 00 00 00
					39 01 00 00 00 00 06 F0 55 AA 52 00 00

					//----------------- ##Frame rate=60Hz-----------------
					39 01 00 00 00 00 02 2F 01
					05 01 00 00 78 00 01 11
					05 01 00 00 00 00 01 29
					];

				qcom,mdss-dsi-off-command = [
					39 01 00 00 00 00 06 F0 55 AA 52 08 01
					39 01 00 00 00 00 02 CE 0C
					05 01 00 00 78 00 01 28
					05 01 00 00 96 00 01 10
				];

				qcom,compression-mode = "dsc";
				qcom,mdss-dsc-version = <0x11>;
				qcom,mdss-dsc-scr-version = <0x0>;
				qcom,mdss-dsc-slice-height = <40>;
				qcom,mdss-dsc-slice-width = <1080>;
				qcom,mdss-dsc-slice-per-pkt = <1>;
				qcom,mdss-dsc-bit-per-component = <8>;
				qcom,mdss-dsc-bit-per-pixel = <8>;
				qcom,mdss-dsc-encoders = <1>;
				qcom,mdss-dsc-block-prediction-enable;

				qcom,mdss-dsi-on-command-state = "dsi_lp_mode";
				qcom,mdss-dsi-off-command-state = "dsi_lp_mode";

				qcom,mode-control-dsi-state = "dsi_lp_mode";
				qcom,mdss-dsi-pps-command-state = "dsi_hs_mode";
			};
		};
	};
};

&sde_dsi1 {
	status = "disabled";
};

&mdss_dsi1 {
	status = "disabled";
};
